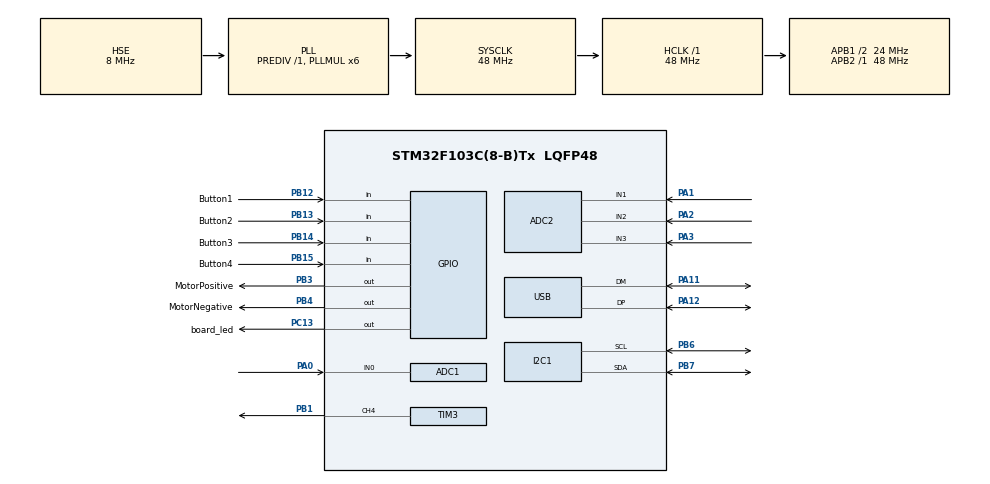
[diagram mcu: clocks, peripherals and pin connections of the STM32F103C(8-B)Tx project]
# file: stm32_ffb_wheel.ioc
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ADC1.Channel-7\#ChannelRegularConversion=ADC_CHANNEL_0
ADC1.ContinuousConvMode=DISABLE
ADC1.EnableInjectedConversion=DISABLE
ADC1.EnableRegularConversion=ENABLE
ADC1.NbrOfConversionFlag=1
ADC1.Rank-7\#ChannelRegularConversion=1
ADC1.SamplingTime-7\#ChannelRegularConversion=ADC_SAMPLETIME_239CYCLES_5
ADC1.master=1
ADC2.Channel-2\#ChannelRegularConversion=ADC_CHANNEL_1
ADC2.NbrOfConversionFlag=1
ADC2.Rank-2\#ChannelRegularConversion=1
ADC2.SamplingTime-2\#ChannelRegularConversion=ADC_SAMPLETIME_239CYCLES_5
Mcu.Family=STM32F1
Mcu.Name=STM32F103C(8-B)Tx
Mcu.Package=LQFP48
NVIC.PriorityGroup=NVIC_PRIORITYGROUP_4
NVIC.USB_LP_CAN1_RX0_IRQn=true\:0\:0\:false\:false\:true\:false\:true\:true
PA0-WKUP.Signal=ADCx_IN0
PA1.Signal=ADCx_IN1
PA11.Mode=Device
PA11.Signal=USB_DM
PA12.Mode=Device
PA12.Signal=USB_DP
PA2.Signal=ADCx_IN2
PA3.Signal=ADCx_IN3
PB1.Signal=S_TIM3_CH4
PB12.GPIO_Label=Button1
PB12.Signal=GPIO_Input
PB13.GPIO_Label=Button2
PB13.Signal=GPIO_Input
PB14.GPIO_Label=Button3
PB14.Signal=GPIO_Input
PB15.GPIO_Label=Button4
PB15.Signal=GPIO_Input
PB3.GPIO_Label=MotorPositive
PB3.Signal=GPIO_Output
PB4.GPIO_Label=MotorNegative
PB4.Signal=GPIO_Output
PB6.Mode=I2C
PB6.Signal=I2C1_SCL
PB7.Mode=I2C
PB7.Signal=I2C1_SDA
PC13-TAMPER-RTC.GPIO_Label=board_led
PC13-TAMPER-RTC.Signal=GPIO_Output
PD0-OSC_IN.Mode=HSE-External-Oscillator
PD0-OSC_IN.Signal=RCC_OSC_IN
PD1-OSC_OUT.Mode=HSE-External-Oscillator
PD1-OSC_OUT.Signal=RCC_OSC_OUT
ProjectManager.HeapSize=0x200
ProjectManager.StackSize=0x400
ProjectManager.TargetToolchain=CMake
RCC.ADCPresc=RCC_ADCPCLK2_DIV4
RCC.AHBFreq_Value=48000000
RCC.APB1CLKDivider=RCC_HCLK_DIV2
RCC.APB1Freq_Value=24000000
RCC.APB1TimFreq_Value=48000000
RCC.APB2Freq_Value=48000000
RCC.APB2TimFreq_Value=48000000
RCC.HCLKFreq_Value=48000000
RCC.PLLMUL=RCC_PLL_MUL6
RCC.SYSCLKFreq_VALUE=48000000
RCC.SYSCLKSource=RCC_SYSCLKSOURCE_PLLCLK
RCC.USBFreq_Value=48000000
SH.ADCx_IN0.0=ADC1_IN0,IN0
SH.ADCx_IN1.0=ADC2_IN1,IN1
SH.ADCx_IN2.0=ADC2_IN2,IN2
SH.ADCx_IN3.0=ADC2_IN3,IN3
SH.S_TIM3_CH4.0=TIM3_CH4,PWM Generation4 CH4
TIM3.Channel-PWM\ Generation4\ CH4=TIM_CHANNEL_4
TIM3.Period=16383
TIM3.Prescaler=0
TIM3.Pulse-PWM\ Generation4\ CH4=0
USB_DEVICE.CLASS_NAME_FS=CUSTOM_HID
USB_DEVICE.MANUFACTURER_STRING=STM32
USB_DEVICE.PID_CUSTOMHID_FS=8270
USB_DEVICE.PRODUCT_STRING_CUSTOMHID_FS=FFB Steering wheel
USB_DEVICE.USBD_CUSTOMHID_OUTREPORT_BUF_SIZE=64
USB_DEVICE.USBD_CUSTOM_HID_REPORT_DESC_SIZE=95
USB_DEVICE.VID=1003
USB_DEVICE.VirtualMode=CustomHid
USB_DEVICE.VirtualModeFS=Custom_Hid_FS
VP_SYS_VS_ND.Mode=No_Debug
VP_USB_DEVICE_VS_USB_DEVICE_CUSTOM_HID_FS.Mode=CUSTOM_HID_FS
board=custom

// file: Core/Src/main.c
/* USER CODE BEGIN Header */
/**
 ******************************************************************************
 * @file           : main.c
 * @brief          : Main program body
 ******************************************************************************
 * @attention
 *
 * Copyright (c) 2024 STMicroelectronics.
 * All rights reserved.
 *
 * This software is licensed under terms that can be found in the LICENSE file
 * in the root directory of this software component.
 * If no LICENSE file comes with this software, it is provided AS-IS.
 *
 ******************************************************************************
 */
/* USER CODE END Header */
#include "main.h"
#include "stm32f1xx_hal_gpio.h"
#include "usb_device.h"

/* USER CODE BEGIN Includes */
#include "steering_wheel_driver.h"
/* USER CODE END Includes */

ADC_HandleTypeDef hadc1;
ADC_HandleTypeDef hadc2;

I2C_HandleTypeDef hi2c1;

TIM_HandleTypeDef htim3;

/* USER CODE BEGIN PV */
SteeringWheelDriver steering_wheel_driver;
/* USER CODE END PV */

void SystemClock_Config(void);
static void MX_GPIO_Init(void);
static void MX_ADC1_Init(void);
static void MX_ADC2_Init(void);
static void MX_TIM3_Init(void);
void MX_I2C1_Init(void);

/* USER CODE BEGIN 0 */
void user_main(void);
/* USER CODE END 0 */

int main(void)
{

  /* MCU Configuration--------------------------------------------------------*/

  /* Reset of all peripherals, Initializes the Flash interface and the Systick. */
  HAL_Init();

  /* Configure the system clock */
  SystemClock_Config();

  /* Initialize all configured peripherals */
  MX_GPIO_Init();
  MX_USB_DEVICE_Init();
  MX_ADC1_Init();
  MX_ADC2_Init();
  MX_TIM3_Init();
  MX_I2C1_Init();
  /* USER CODE BEGIN 2 */
  HAL_TIM_PWM_Start(&htim3, TIM_CHANNEL_4);
  SteeringWheelDriver_Init(&steering_wheel_driver);
  /* USER CODE END 2 */

  /* Infinite loop */
  while (1) {

    /* USER CODE BEGIN 3 */
    user_main();
  }
  /* USER CODE END 3 */
}

void SystemClock_Config(void)
{
  RCC_OscInitTypeDef RCC_OscInitStruct = {0};
  RCC_ClkInitTypeDef RCC_ClkInitStruct = {0};
  RCC_PeriphCLKInitTypeDef PeriphClkInit = {0};

  /** Initializes the RCC Oscillators according to the specified parameters
  * in the RCC_OscInitTypeDef structure.
  */
  RCC_OscInitStruct.OscillatorType = RCC_OSCILLATORTYPE_HSE;
  RCC_OscInitStruct.HSEState = RCC_HSE_ON;
  RCC_OscInitStruct.HSEPredivValue = RCC_HSE_PREDIV_DIV1;
  RCC_OscInitStruct.HSIState = RCC_HSI_ON;
  RCC_OscInitStruct.PLL.PLLState = RCC_PLL_ON;
  RCC_OscInitStruct.PLL.PLLSource = RCC_PLLSOURCE_HSE;
  RCC_OscInitStruct.PLL.PLLMUL = RCC_PLL_MUL6;
  if (HAL_RCC_OscConfig(&RCC_OscInitStruct) != HAL_OK)
  {
    Error_Handler();
  }

  /** Initializes the CPU, AHB and APB buses clocks
  */
  RCC_ClkInitStruct.ClockType = RCC_CLOCKTYPE_HCLK|RCC_CLOCKTYPE_SYSCLK
                              |RCC_CLOCKTYPE_PCLK1|RCC_CLOCKTYPE_PCLK2;
  RCC_ClkInitStruct.SYSCLKSource = RCC_SYSCLKSOURCE_PLLCLK;
  RCC_ClkInitStruct.AHBCLKDivider = RCC_SYSCLK_DIV1;
  RCC_ClkInitStruct.APB1CLKDivider = RCC_HCLK_DIV2;
  RCC_ClkInitStruct.APB2CLKDivider = RCC_HCLK_DIV1;

  if (HAL_RCC_ClockConfig(&RCC_ClkInitStruct, FLASH_LATENCY_1) != HAL_OK)
  {
    Error_Handler();
  }
  PeriphClkInit.PeriphClockSelection = RCC_PERIPHCLK_ADC|RCC_PERIPHCLK_USB;
  PeriphClkInit.AdcClockSelection = RCC_ADCPCLK2_DIV4;
  PeriphClkInit.UsbClockSelection = RCC_USBCLKSOURCE_PLL;
  if (HAL_RCCEx_PeriphCLKConfig(&PeriphClkInit) != HAL_OK)
  {
    Error_Handler();
  }
}

static void MX_ADC1_Init(void)
{

  ADC_ChannelConfTypeDef sConfig = {0};

  /** Common config
  */
  hadc1.Instance = ADC1;
  hadc1.Init.ScanConvMode = ADC_SCAN_DISABLE;
  hadc1.Init.ContinuousConvMode = DISABLE;
  hadc1.Init.DiscontinuousConvMode = DISABLE;
  hadc1.Init.ExternalTrigConv = ADC_SOFTWARE_START;
  hadc1.Init.DataAlign = ADC_DATAALIGN_RIGHT;
  hadc1.Init.NbrOfConversion = 1;
  if (HAL_ADC_Init(&hadc1) != HAL_OK)
  {
    Error_Handler();
  }

  /** Configure Regular Channel
  */
  sConfig.Channel = ADC_CHANNEL_0;
  sConfig.Rank = ADC_REGULAR_RANK_1;
  sConfig.SamplingTime = ADC_SAMPLETIME_239CYCLES_5;
  if (HAL_ADC_ConfigChannel(&hadc1, &sConfig) != HAL_OK)
  {
    Error_Handler();
  }

}

static void MX_ADC2_Init(void)
{

  ADC_ChannelConfTypeDef sConfig = {0};

  /** Common config
  */
  hadc2.Instance = ADC2;
  hadc2.Init.ScanConvMode = ADC_SCAN_DISABLE;
  hadc2.Init.ContinuousConvMode = DISABLE;
  hadc2.Init.DiscontinuousConvMode = DISABLE;
  hadc2.Init.ExternalTrigConv = ADC_SOFTWARE_START;
  hadc2.Init.DataAlign = ADC_DATAALIGN_RIGHT;
  hadc2.Init.NbrOfConversion = 1;
  if (HAL_ADC_Init(&hadc2) != HAL_OK)
  {
    Error_Handler();
  }

  /** Configure Regular Channel
  */
  sConfig.Channel = ADC_CHANNEL_1;
  sConfig.Rank = ADC_REGULAR_RANK_1;
  sConfig.SamplingTime = ADC_SAMPLETIME_239CYCLES_5;
  if (HAL_ADC_ConfigChannel(&hadc2, &sConfig) != HAL_OK)
  {
    Error_Handler();
  }

}

void MX_I2C1_Init(void)
{

  hi2c1.Instance = I2C1;
  hi2c1.Init.ClockSpeed = 100000;
  hi2c1.Init.DutyCycle = I2C_DUTYCYCLE_2;
  hi2c1.Init.OwnAddress1 = 0;
  hi2c1.Init.AddressingMode = I2C_ADDRESSINGMODE_7BIT;
  hi2c1.Init.DualAddressMode = I2C_DUALADDRESS_DISABLE;
  hi2c1.Init.OwnAddress2 = 0;
  hi2c1.Init.GeneralCallMode = I2C_GENERALCALL_DISABLE;
  hi2c1.Init.NoStretchMode = I2C_NOSTRETCH_DISABLE;
  if (HAL_I2C_Init(&hi2c1) != HAL_OK)
  {
    Error_Handler();
  }

}

static void MX_TIM3_Init(void)
{

  TIM_MasterConfigTypeDef sMasterConfig = {0};
  TIM_OC_InitTypeDef sConfigOC = {0};

  htim3.Instance = TIM3;
  htim3.Init.Prescaler = 0;
  htim3.Init.CounterMode = TIM_COUNTERMODE_UP;
  htim3.Init.Period = 4095;
  htim3.Init.ClockDivision = TIM_CLOCKDIVISION_DIV1;
  htim3.Init.AutoReloadPreload = TIM_AUTORELOAD_PRELOAD_DISABLE;
  if (HAL_TIM_PWM_Init(&htim3) != HAL_OK)
  {
    Error_Handler();
  }
  sMasterConfig.MasterOutputTrigger = TIM_TRGO_RESET;
  sMasterConfig.MasterSlaveMode = TIM_MASTERSLAVEMODE_DISABLE;
  if (HAL_TIMEx_MasterConfigSynchronization(&htim3, &sMasterConfig) != HAL_OK)
  {
    Error_Handler();
  }
  sConfigOC.OCMode = TIM_OCMODE_PWM1;
  sConfigOC.Pulse = 0;
  sConfigOC.OCPolarity = TIM_OCPOLARITY_HIGH;
  sConfigOC.OCFastMode = TIM_OCFAST_DISABLE;
  if (HAL_TIM_PWM_ConfigChannel(&htim3, &sConfigOC, TIM_CHANNEL_4) != HAL_OK)
  {
    Error_Handler();
  }
  HAL_TIM_MspPostInit(&htim3);

}

static void MX_GPIO_Init(void)
{
  GPIO_InitTypeDef GPIO_InitStruct = {0};

  /* GPIO Ports Clock Enable */
  __HAL_RCC_GPIOC_CLK_ENABLE();
  __HAL_RCC_GPIOD_CLK_ENABLE();
  __HAL_RCC_GPIOA_CLK_ENABLE();
  __HAL_RCC_GPIOB_CLK_ENABLE();

  /*Configure GPIO pin Output Level */
  HAL_GPIO_WritePin(board_led_GPIO_Port, board_led_Pin, GPIO_PIN_RESET);

  /*Configure GPIO pin Output Level */
  HAL_GPIO_WritePin(MotorNegative_Pin_GPIO_Port, MotorNegative_Pin, GPIO_PIN_RESET);
  HAL_GPIO_WritePin(MotorPositive_Pin_GPIO_Port, MotorPositive_Pin, GPIO_PIN_RESET);

  /*Configure GPIO pin : board_led_Pin */
  GPIO_InitStruct.Pin = board_led_Pin;
  GPIO_InitStruct.Mode = GPIO_MODE_OUTPUT_PP;
  GPIO_InitStruct.Pull = GPIO_NOPULL;
  GPIO_InitStruct.Speed = GPIO_SPEED_FREQ_LOW;
  HAL_GPIO_Init(board_led_GPIO_Port, &GPIO_InitStruct);

  /*Configure GPIO pins : Button1_Pin Button2_Pin Button3_Pin Button4_Pin */
  GPIO_InitStruct.Pin = Button1_Pin|Button2_Pin|Button3_Pin|Button4_Pin;
  GPIO_InitStruct.Mode = GPIO_MODE_INPUT;
  GPIO_InitStruct.Pull = GPIO_NOPULL;
  HAL_GPIO_Init(GPIOB, &GPIO_InitStruct);

  /*Configure GPIO pins : MotorPositive_Pin MotorNegative_Pin */
  GPIO_InitStruct.Pin = MotorNegative_Pin|MotorPositive_Pin;
  GPIO_InitStruct.Mode = GPIO_MODE_OUTPUT_PP;
  GPIO_InitStruct.Pull = GPIO_NOPULL;
  GPIO_InitStruct.Speed = GPIO_SPEED_FREQ_LOW;
  HAL_GPIO_Init(MotorPositive_Pin_GPIO_Port, &GPIO_InitStruct);

}

void Error_Handler(void)
{
  __disable_irq();
  while (1) {
  }
}

#ifdef  USE_FULL_ASSERT
/**
  * @brief  Reports the name of the source file and the source line number
  *         where the assert_param error has occurred.
  * @param  file: pointer to the source file name
  * @param  line: assert_param error line source number
  * @retval None
  */
void assert_failed(uint8_t *file, uint32_t line)
{
  /* USER CODE BEGIN 6 */
  /* User can add his own implementation to report the file name and line
     number, ex: printf("Wrong parameters value: file %s on line %d\r\n", file,
     line) */
  /* USER CODE END 6 */
}
#endif /* USE_FULL_ASSERT */
